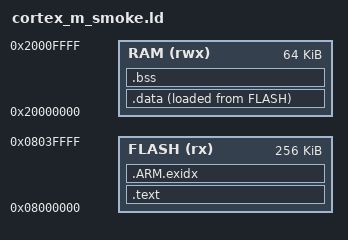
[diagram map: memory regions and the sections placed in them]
/* Link-only fixture. No board vector table or startup is implied. */
ENTRY(_start)
MEMORY {
  FLASH (rx) : ORIGIN = 0x08000000, LENGTH = 256K
  RAM (rwx) : ORIGIN = 0x20000000, LENGTH = 64K
}
SECTIONS {
  .text : { *(.text*) *(.rodata*) } > FLASH
  .ARM.exidx : { *(.ARM.exidx*) } > FLASH
  .data : { *(.data*) } > RAM AT> FLASH
  .bss (NOLOAD) : { *(.bss*) *(COMMON) } > RAM
}
